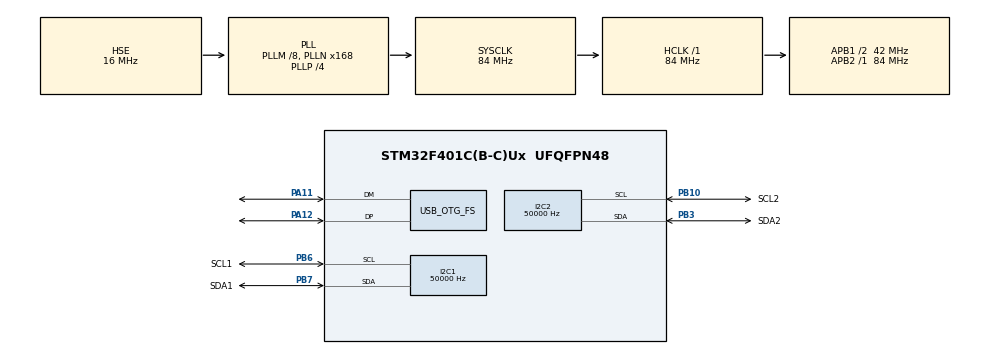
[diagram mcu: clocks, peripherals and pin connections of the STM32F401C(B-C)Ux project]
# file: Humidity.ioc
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I2C1.ClockSpeed=50000
I2C2.ClockSpeed=50000
IWDG.Prescaler=IWDG_PRESCALER_16
Mcu.Family=STM32F4
Mcu.Name=STM32F401C(B-C)Ux
Mcu.Package=UFQFPN48
NVIC.OTG_FS_IRQn=true\:0\:0\:false\:false\:true\:false\:true\:true
NVIC.PriorityGroup=NVIC_PRIORITYGROUP_4
NVIC.TIM2_IRQn=true\:0\:0\:false\:false\:true\:true\:true\:true
PA11.Mode=Device_Only
PA11.Signal=USB_OTG_FS_DM
PA12.Mode=Device_Only
PA12.Signal=USB_OTG_FS_DP
PA13.Mode=Serial_Wire
PA13.Signal=SYS_JTMS-SWDIO
PA14.Mode=Serial_Wire
PA14.Signal=SYS_JTCK-SWCLK
PB10.GPIO_Label=SCL2
PB10.GPIO_Pu=GPIO_PULLUP
PB10.Mode=I2C
PB10.Signal=I2C2_SCL
PB3.GPIO_Label=SDA2
PB3.GPIO_Pu=GPIO_PULLUP
PB3.Mode=I2C
PB3.Signal=I2C2_SDA
PB6.GPIO_Label=SCL1
PB6.GPIO_Pu=GPIO_PULLUP
PB6.Mode=I2C
PB6.Signal=I2C1_SCL
PB7.GPIO_Label=SDA1
PB7.GPIO_Pu=GPIO_PULLUP
PB7.Mode=I2C
PB7.Signal=I2C1_SDA
PH0\ -\ OSC_IN.Mode=HSE-External-Oscillator
PH0\ -\ OSC_IN.Signal=RCC_OSC_IN
PH1\ -\ OSC_OUT.Mode=HSE-External-Oscillator
PH1\ -\ OSC_OUT.Signal=RCC_OSC_OUT
ProjectManager.HeapSize=0x200
ProjectManager.StackSize=0x400
ProjectManager.TargetToolchain=Makefile
RCC.48MHZClocksFreq_Value=48000000
RCC.AHBFreq_Value=84000000
RCC.APB1CLKDivider=RCC_HCLK_DIV2
RCC.APB1Freq_Value=42000000
RCC.APB1TimFreq_Value=84000000
RCC.APB2Freq_Value=84000000
RCC.APB2TimFreq_Value=84000000
RCC.CortexFreq_Value=84000000
RCC.HCLKFreq_Value=84000000
RCC.HSE_VALUE=16000000
RCC.HSI_VALUE=16000000
RCC.LSE_VALUE=32768
RCC.PLLM=8
RCC.PLLN=168
RCC.PLLP=RCC_PLLP_DIV4
RCC.PLLQ=7
RCC.SYSCLKFreq_VALUE=84000000
RCC.SYSCLKSource=RCC_SYSCLKSOURCE_PLLCLK
RCC.VCOOutputFreq_Value=336000000
TIM2.Period=840000-1
TIM2.Prescaler=10-1
USB_DEVICE.CLASS_NAME_FS=CDC
USB_DEVICE.VirtualMode=Cdc
USB_DEVICE.VirtualModeFS=Cdc_FS
USB_OTG_FS.VirtualMode=Device_Only
VP_CRC_VS_CRC.Mode=CRC_Activate
VP_IWDG_VS_IWDG.Mode=IWDG_Activate
VP_TIM2_VS_ClockSourceINT.Mode=Internal
VP_USB_DEVICE_VS_USB_DEVICE_CDC_FS.Mode=CDC_FS
board=custom

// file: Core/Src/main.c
/* USER CODE BEGIN Header */
/**
  ******************************************************************************
  * @file           : main.c
  * @brief          : Main program body
  ******************************************************************************
  * @attention
  *
  * Copyright (c) 2022 STMicroelectronics.
  * All rights reserved.
  *
  * This software is licensed under terms that can be found in the LICENSE file
  * in the root directory of this software component.
  * If no LICENSE file comes with this software, it is provided AS-IS.
  *
  ******************************************************************************
  */
/* USER CODE END Header */
#include "main.h"
#include "usb_device.h"

/* USER CODE BEGIN Includes */
#include "humidityApp.h"
#include "CAProtocolStm.h"
/* USER CODE END Includes */

CRC_HandleTypeDef hcrc;

I2C_HandleTypeDef hi2c1;
I2C_HandleTypeDef hi2c2;

IWDG_HandleTypeDef hiwdg;

TIM_HandleTypeDef htim2;

void SystemClock_Config(void);
static void MX_GPIO_Init(void);
static void MX_CRC_Init(void);
static void MX_I2C1_Init(void);
static void MX_IWDG_Init(void);
static void MX_I2C2_Init(void);
static void MX_TIM2_Init(void);

int main(void)
{

  /* MCU Configuration--------------------------------------------------------*/

  /* Reset of all peripherals, Initializes the Flash interface and the Systick. */
  HAL_Init();

  /* Configure the system clock */
  SystemClock_Config();

  /* USER CODE BEGIN SysInit */
  const char* bootMsg = CAonBoot();
  /* USER CODE END SysInit */

  /* Initialize all configured peripherals */
  MX_GPIO_Init();
  MX_CRC_Init();
  MX_I2C1_Init();
  MX_USB_DEVICE_Init();
  MX_IWDG_Init();
  MX_I2C2_Init();
  MX_TIM2_Init();
  /* USER CODE BEGIN 2 */
  InitHumidity(&hi2c1, &hi2c2, &hcrc, bootMsg);
  HAL_TIM_Base_Start_IT(&htim2);
  /* USER CODE END 2 */

  /* Infinite loop */
  /* USER CODE BEGIN WHILE */
  while (1)
  {
    HAL_IWDG_Refresh(&hiwdg);
    LoopHumidity(bootMsg);
    /* USER CODE END WHILE */

  }
}

void SystemClock_Config(void)
{
  RCC_OscInitTypeDef RCC_OscInitStruct = {0};
  RCC_ClkInitTypeDef RCC_ClkInitStruct = {0};

  /** Configure the main internal regulator output voltage
  */
  __HAL_RCC_PWR_CLK_ENABLE();
  __HAL_PWR_VOLTAGESCALING_CONFIG(PWR_REGULATOR_VOLTAGE_SCALE2);

  /** Initializes the RCC Oscillators according to the specified parameters
  * in the RCC_OscInitTypeDef structure.
  */
  RCC_OscInitStruct.OscillatorType = RCC_OSCILLATORTYPE_LSI|RCC_OSCILLATORTYPE_HSE;
  RCC_OscInitStruct.HSEState = RCC_HSE_ON;
  RCC_OscInitStruct.LSIState = RCC_LSI_ON;
  RCC_OscInitStruct.PLL.PLLState = RCC_PLL_ON;
  RCC_OscInitStruct.PLL.PLLSource = RCC_PLLSOURCE_HSE;
  RCC_OscInitStruct.PLL.PLLM = 8;
  RCC_OscInitStruct.PLL.PLLN = 168;
  RCC_OscInitStruct.PLL.PLLP = RCC_PLLP_DIV4;
  RCC_OscInitStruct.PLL.PLLQ = 7;
  if (HAL_RCC_OscConfig(&RCC_OscInitStruct) != HAL_OK)
  {
    Error_Handler();
  }

  /** Initializes the CPU, AHB and APB buses clocks
  */
  RCC_ClkInitStruct.ClockType = RCC_CLOCKTYPE_HCLK|RCC_CLOCKTYPE_SYSCLK
                              |RCC_CLOCKTYPE_PCLK1|RCC_CLOCKTYPE_PCLK2;
  RCC_ClkInitStruct.SYSCLKSource = RCC_SYSCLKSOURCE_PLLCLK;
  RCC_ClkInitStruct.AHBCLKDivider = RCC_SYSCLK_DIV1;
  RCC_ClkInitStruct.APB1CLKDivider = RCC_HCLK_DIV2;
  RCC_ClkInitStruct.APB2CLKDivider = RCC_HCLK_DIV1;

  if (HAL_RCC_ClockConfig(&RCC_ClkInitStruct, FLASH_LATENCY_2) != HAL_OK)
  {
    Error_Handler();
  }
}

static void MX_CRC_Init(void)
{

  hcrc.Instance = CRC;
  if (HAL_CRC_Init(&hcrc) != HAL_OK)
  {
    Error_Handler();
  }

}

static void MX_I2C1_Init(void)
{

  hi2c1.Instance = I2C1;
  hi2c1.Init.ClockSpeed = 50000;
  hi2c1.Init.DutyCycle = I2C_DUTYCYCLE_2;
  hi2c1.Init.OwnAddress1 = 0;
  hi2c1.Init.AddressingMode = I2C_ADDRESSINGMODE_7BIT;
  hi2c1.Init.DualAddressMode = I2C_DUALADDRESS_DISABLE;
  hi2c1.Init.OwnAddress2 = 0;
  hi2c1.Init.GeneralCallMode = I2C_GENERALCALL_DISABLE;
  hi2c1.Init.NoStretchMode = I2C_NOSTRETCH_DISABLE;
  if (HAL_I2C_Init(&hi2c1) != HAL_OK)
  {
    Error_Handler();
  }

}

static void MX_I2C2_Init(void)
{

  hi2c2.Instance = I2C2;
  hi2c2.Init.ClockSpeed = 50000;
  hi2c2.Init.DutyCycle = I2C_DUTYCYCLE_2;
  hi2c2.Init.OwnAddress1 = 0;
  hi2c2.Init.AddressingMode = I2C_ADDRESSINGMODE_7BIT;
  hi2c2.Init.DualAddressMode = I2C_DUALADDRESS_DISABLE;
  hi2c2.Init.OwnAddress2 = 0;
  hi2c2.Init.GeneralCallMode = I2C_GENERALCALL_DISABLE;
  hi2c2.Init.NoStretchMode = I2C_NOSTRETCH_DISABLE;
  if (HAL_I2C_Init(&hi2c2) != HAL_OK)
  {
    Error_Handler();
  }

}

static void MX_IWDG_Init(void)
{

  hiwdg.Instance = IWDG;
  hiwdg.Init.Prescaler = IWDG_PRESCALER_16;
  hiwdg.Init.Reload = 4095;
  if (HAL_IWDG_Init(&hiwdg) != HAL_OK)
  {
    Error_Handler();
  }

}

static void MX_TIM2_Init(void)
{

  TIM_ClockConfigTypeDef sClockSourceConfig = {0};
  TIM_MasterConfigTypeDef sMasterConfig = {0};

  htim2.Instance = TIM2;
  htim2.Init.Prescaler = 10-1;
  htim2.Init.CounterMode = TIM_COUNTERMODE_UP;
  htim2.Init.Period = 840000-1;
  htim2.Init.ClockDivision = TIM_CLOCKDIVISION_DIV1;
  htim2.Init.AutoReloadPreload = TIM_AUTORELOAD_PRELOAD_DISABLE;
  if (HAL_TIM_Base_Init(&htim2) != HAL_OK)
  {
    Error_Handler();
  }
  sClockSourceConfig.ClockSource = TIM_CLOCKSOURCE_INTERNAL;
  if (HAL_TIM_ConfigClockSource(&htim2, &sClockSourceConfig) != HAL_OK)
  {
    Error_Handler();
  }
  sMasterConfig.MasterOutputTrigger = TIM_TRGO_RESET;
  sMasterConfig.MasterSlaveMode = TIM_MASTERSLAVEMODE_DISABLE;
  if (HAL_TIMEx_MasterConfigSynchronization(&htim2, &sMasterConfig) != HAL_OK)
  {
    Error_Handler();
  }

}

static void MX_GPIO_Init(void)
{

  /* GPIO Ports Clock Enable */
  __HAL_RCC_GPIOH_CLK_ENABLE();
  __HAL_RCC_GPIOB_CLK_ENABLE();
  __HAL_RCC_GPIOA_CLK_ENABLE();

}

void Error_Handler(void)
{
  __disable_irq();
  while (1)
  {
  }
}
